# R5SS_ECC_AGG_CORE0_53000000h register map
Vendor: Texas Instruments
Peripheral module from a debugger description file (folder AM263P).
Registers are 32-bit, access not given, reset 0x0 unless marked. A register's access mark holds for its fields unless they carry their own. Offsets are as the file gives them; lines under a group give offsets from that group; [hi:lo] are bit positions; {n}, {i} and the like mark numbered series; 'fields as' and 'values as' point back to an identical list; <NAME> marks a mode.

## ECC_AGG_CORE0
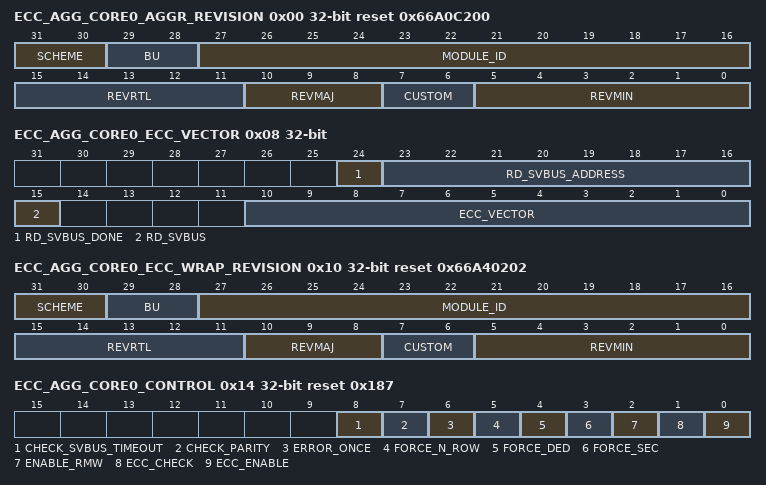
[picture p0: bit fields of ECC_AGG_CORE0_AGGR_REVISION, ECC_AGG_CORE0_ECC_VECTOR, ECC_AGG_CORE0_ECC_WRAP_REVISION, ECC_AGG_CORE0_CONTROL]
0x00 ECC_AGG_CORE0_AGGR_REVISION ro reset 0x66A0C200 — Revision parameters register. The Revision Register contains the major and minor revisions for the ECC aggregator module. It does notsupport byte accesses.
  [31:30] SCHEME
  [29:28] BU
  [27:16] MODULE_ID
  [15:11] REVRTL — RTL version
  [10:8] REVMAJ — Major version
  [7:6] CUSTOM — Custom version
  [5:0] REVMIN — Minor version
0x08 ECC_AGG_CORE0_ECC_VECTOR — ECC Vector Register. ECC RAM ID to select which ECC RAM to control or read status from.
  [24] RD_SVBUS_DONE ro — Status to indicate if read on serial VBUS is complete
  [23:16] RD_SVBUS_ADDRESS rw — Read address
  [15] RD_SVBUS — Write 1 to trigger a read on the serial VBUS (access R/W1TS)
  [10:0] ECC_VECTOR rw — Value written to select the corresponding ECC RAM for control or status
0x0C ECC_AGG_CORE0_MISC_STATUS ro reset 0x1D — Misc Statu register. It contains misc status such as number of ECC RAMs serviced by the ECC aggregator.
  [10:0] NUM_RAMS — Indicates the number of RAMS serviced by the ECC aggregator
0x10 ECC_AGG_CORE0_ECC_WRAP_REVISION ro reset 0x66A40202 — Revision parameters.
  fields as ECC_AGG_CORE0_AGGR_REVISION
0x14 ECC_AGG_CORE0_CONTROL rw reset 0x187 — ECC Control Register.
  [8] CHECK_SVBUS_TIMEOUT — check for svbus timeout errors
  [7] CHECK_PARITY — check for parity errors
  [6] ERROR_ONCE — Force Error only once
  [5] FORCE_N_ROW — Force Error on any RAM read
  [4] FORCE_DED — Force Double Bit Error
  [3] FORCE_SEC — Force Single Bit Error
  [2] ENABLE_RMW
  [1] ECC_CHECK — Enable ECC check
  [0] ECC_ENABLE — Enable ECC
0x18 ECC_AGG_CORE0_ERROR_CTRL1 rw — ECC Error Control1 Register.
  [31:0] ECC_ROW — Row address where single or double-bit error needs to be applied. This is ignored if force_n_row is set
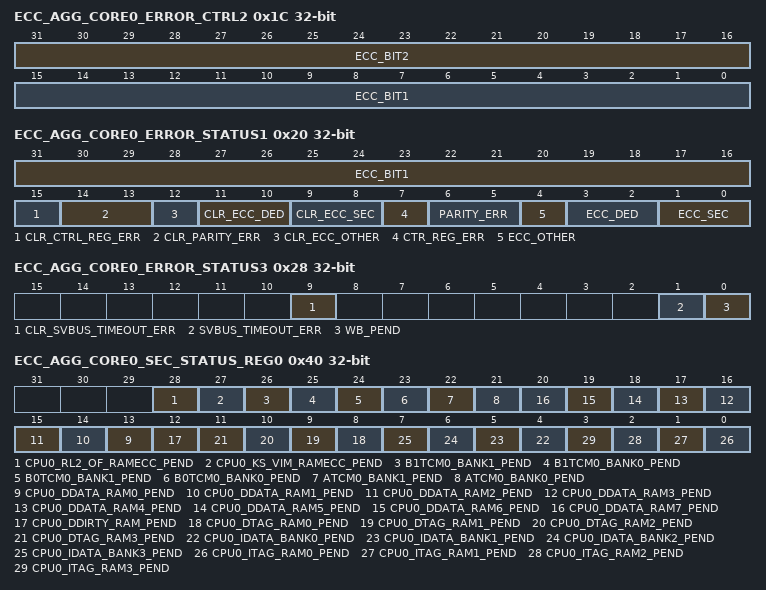
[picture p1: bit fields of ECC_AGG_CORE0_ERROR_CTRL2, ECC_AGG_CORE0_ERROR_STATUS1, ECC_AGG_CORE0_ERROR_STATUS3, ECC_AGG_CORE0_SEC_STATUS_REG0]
0x1C ECC_AGG_CORE0_ERROR_CTRL2 rw — ECC Error Control2 Register.
  [31:16] ECC_BIT2 — Data bit that needs to be flipped if double bit error needs to be forced
  [15:0] ECC_BIT1 — Data bit that needs to be flipped when force_sec is set
0x20 ECC_AGG_CORE0_ERROR_STATUS1 — ECC Error Status1 Register.
  [31:16] ECC_BIT1 ro — Data bit that corresponds to the single-bit error
  [15] CLR_CTRL_REG_ERR — Clear control reg error Error Status, you must also re write the contorl ergister itself to clear this (access R/W1TC)
  [14:13] CLR_PARITY_ERR — Clear parity Error Status (access R/WD)
  [12] CLR_ECC_OTHER — Clear other Error Status (access R/W1TC)
  [11:10] CLR_ECC_DED — Clear Double Bit Error Status (access R/WD)
  [9:8] CLR_ECC_SEC — Clear Single Bit Error Status (access R/WD)
  [7] CTR_REG_ERR — control register error pending, Level interrupt (access R/W1TS)
  [6:5] PARITY_ERR — Level parity error Error Status (access R/W1TS)
  [4] ECC_OTHER — Successive single-bit errors have occurred while a writeback is still pending, Level interrupt (access R/W1TS)
  [3:2] ECC_DED — Level Double Bit Error Status (access R/WI)
  [1:0] ECC_SEC — Level Single Bit Error Status (access R/WI)
0x24 ECC_AGG_CORE0_ERROR_STATUS2 ro — ECC Error Status2 Register.
  [31:0] ECC_ROW — Row address where the single or double-bit error has occurred
0x28 ECC_AGG_CORE0_ERROR_STATUS3 — ECC Error Status3 Register.
  [9] CLR_SVBUS_TIMEOUT_ERR — Clear svbus timeout Error Status (access R/W1TC)
  [1] SVBUS_TIMEOUT_ERR — Level svbus timeout error Error Status (access R/W1TS)
  [0] WB_PEND ro — delayed write back pending Status
0x3C ECC_AGG_CORE0_SEC_EOI_REG — EOI Register.
  [0] EOI_WR — EOI Register (access R/W1TS)
0x40 ECC_AGG_CORE0_SEC_STATUS_REG0 — Interrupt Status Register 0
  [28] CPU0_RL2_OF_RAMECC_PEND — Interrupt Pending Status for cpu0_rl2_of_ramecc_pend (access R/W1TS)
  [27] CPU0_KS_VIM_RAMECC_PEND — Interrupt Pending Status for cpu0_ks_vim_ramecc_pend (access R/W1TS)
  [26] B1TCM0_BANK1_PEND — Interrupt Pending Status for b1tcm0_bank1_pend (access R/W1TS)
  [25] B1TCM0_BANK0_PEND — Interrupt Pending Status for b1tcm0_bank0_pend (access R/W1TS)
  [24] B0TCM0_BANK1_PEND — Interrupt Pending Status for b0tcm0_bank1_pend (access R/W1TS)
  [23] B0TCM0_BANK0_PEND — Interrupt Pending Status for b0tcm0_bank0_pend (access R/W1TS)
  [22] ATCM0_BANK1_PEND — Interrupt Pending Status for atcm0_bank1_pend (access R/W1TS)
  [21] ATCM0_BANK0_PEND — Interrupt Pending Status for atcm0_bank0_pend (access R/W1TS)
  [n+13] CPU0_DDATA_RAM{n}_PEND (n=0..7) — Interrupt Pending Status for cpu0_ddata_ram{n}_pend (access R/W1TS)
  [12] CPU0_DDIRTY_RAM_PEND — Interrupt Pending Status for cpu0_ddirty_ram_pend (access R/W1TS)
  [n+8] CPU0_DTAG_RAM{n}_PEND (n=0..3) — Interrupt Pending Status for cpu0_dtag_ram{n}_pend (access R/W1TS)
  [n+4] CPU0_IDATA_BANK{n}_PEND (n=0..3) — Interrupt Pending Status for cpu0_idata_bank{n}_pend (access R/W1TS)
  [n] CPU0_ITAG_RAM{n}_PEND (n=0..3) — Interrupt Pending Status for cpu0_itag_ram{n}_pend (access R/W1TS)
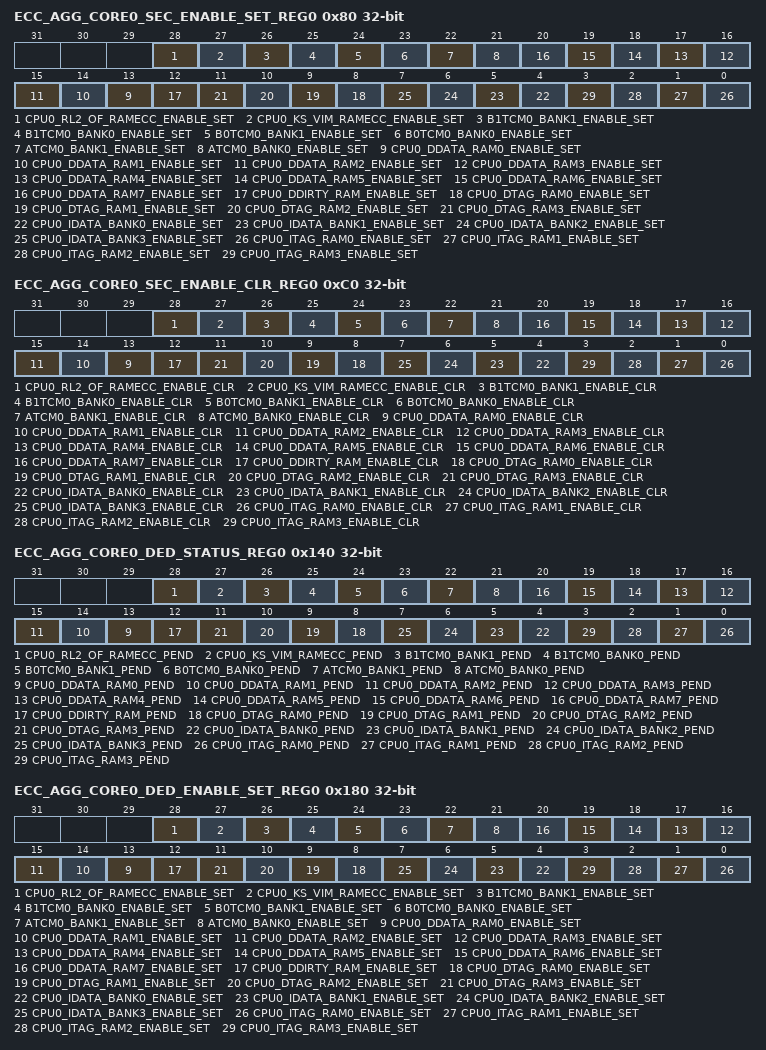
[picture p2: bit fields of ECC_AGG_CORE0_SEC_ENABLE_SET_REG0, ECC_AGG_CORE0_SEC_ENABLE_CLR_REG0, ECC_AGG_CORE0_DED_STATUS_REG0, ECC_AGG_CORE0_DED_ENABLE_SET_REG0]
0x80 ECC_AGG_CORE0_SEC_ENABLE_SET_REG0 — Interrupt Enable Set Register 0
  [28] CPU0_RL2_OF_RAMECC_ENABLE_SET — Interrupt Enable Set Register for cpu0_rl2_of_ramecc_pend (access R/W1TS)
  [27] CPU0_KS_VIM_RAMECC_ENABLE_SET — Interrupt Enable Set Register for cpu0_ks_vim_ramecc_pend (access R/W1TS)
  [26] B1TCM0_BANK1_ENABLE_SET — Interrupt Enable Set Register for b1tcm0_bank1_pend (access R/W1TS)
  [25] B1TCM0_BANK0_ENABLE_SET — Interrupt Enable Set Register for b1tcm0_bank0_pend (access R/W1TS)
  [24] B0TCM0_BANK1_ENABLE_SET — Interrupt Enable Set Register for b0tcm0_bank1_pend (access R/W1TS)
  [23] B0TCM0_BANK0_ENABLE_SET — Interrupt Enable Set Register for b0tcm0_bank0_pend (access R/W1TS)
  [22] ATCM0_BANK1_ENABLE_SET — Interrupt Enable Set Register for atcm0_bank1_pend (access R/W1TS)
  [21] ATCM0_BANK0_ENABLE_SET — Interrupt Enable Set Register for atcm0_bank0_pend (access R/W1TS)
  [n+13] CPU0_DDATA_RAM{n}_ENABLE_SET (n=0..7) — Interrupt Enable Set Register for cpu0_ddata_ram{n}_pend (access R/W1TS)
  [12] CPU0_DDIRTY_RAM_ENABLE_SET — Interrupt Enable Set Register for cpu0_ddirty_ram_pend (access R/W1TS)
  [n+8] CPU0_DTAG_RAM{n}_ENABLE_SET (n=0..3) — Interrupt Enable Set Register for cpu0_dtag_ram{n}_pend (access R/W1TS)
  [n+4] CPU0_IDATA_BANK{n}_ENABLE_SET (n=0..3) — Interrupt Enable Set Register for cpu0_idata_bank{n}_pend (access R/W1TS)
  [n] CPU0_ITAG_RAM{n}_ENABLE_SET (n=0..3) — Interrupt Enable Set Register for cpu0_itag_ram{n}_pend (access R/W1TS)
0xC0 ECC_AGG_CORE0_SEC_ENABLE_CLR_REG0 — Interrupt Enable Clear Register 0
  [28] CPU0_RL2_OF_RAMECC_ENABLE_CLR — Interrupt Enable Clear Register for cpu0_rl2_of_ramecc_pend (access R/W1TC)
  [27] CPU0_KS_VIM_RAMECC_ENABLE_CLR — Interrupt Enable Clear Register for cpu0_ks_vim_ramecc_pend (access R/W1TC)
  [26] B1TCM0_BANK1_ENABLE_CLR — Interrupt Enable Clear Register for b1tcm0_bank1_pend (access R/W1TC)
  [25] B1TCM0_BANK0_ENABLE_CLR — Interrupt Enable Clear Register for b1tcm0_bank0_pend (access R/W1TC)
  [24] B0TCM0_BANK1_ENABLE_CLR — Interrupt Enable Clear Register for b0tcm0_bank1_pend (access R/W1TC)
  [23] B0TCM0_BANK0_ENABLE_CLR — Interrupt Enable Clear Register for b0tcm0_bank0_pend (access R/W1TC)
  [22] ATCM0_BANK1_ENABLE_CLR — Interrupt Enable Clear Register for atcm0_bank1_pend (access R/W1TC)
  [21] ATCM0_BANK0_ENABLE_CLR — Interrupt Enable Clear Register for atcm0_bank0_pend (access R/W1TC)
  [n+13] CPU0_DDATA_RAM{n}_ENABLE_CLR (n=0..7) — Interrupt Enable Clear Register for cpu0_ddata_ram{n}_pend (access R/W1TC)
  [12] CPU0_DDIRTY_RAM_ENABLE_CLR — Interrupt Enable Clear Register for cpu0_ddirty_ram_pend (access R/W1TC)
  [n+8] CPU0_DTAG_RAM{n}_ENABLE_CLR (n=0..3) — Interrupt Enable Clear Register for cpu0_dtag_ram{n}_pend (access R/W1TC)
  [n+4] CPU0_IDATA_BANK{n}_ENABLE_CLR (n=0..3) — Interrupt Enable Clear Register for cpu0_idata_bank{n}_pend (access R/W1TC)
  [n] CPU0_ITAG_RAM{n}_ENABLE_CLR (n=0..3) — Interrupt Enable Clear Register for cpu0_itag_ram{n}_pend (access R/W1TC)
0x13C ECC_AGG_CORE0_DED_EOI_REG — EOI Register.
  [0] EOI_WR — EOI Register (access R/W1TS)
0x140 ECC_AGG_CORE0_DED_STATUS_REG0 — Interrupt Status Register 0
  fields as ECC_AGG_CORE0_SEC_STATUS_REG0
0x180 ECC_AGG_CORE0_DED_ENABLE_SET_REG0 — Interrupt Enable Set Register 0
  fields as ECC_AGG_CORE0_SEC_ENABLE_SET_REG0
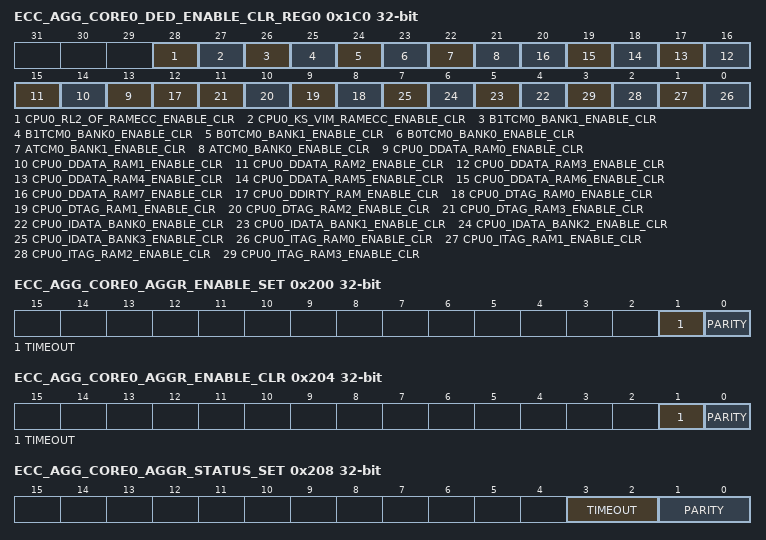
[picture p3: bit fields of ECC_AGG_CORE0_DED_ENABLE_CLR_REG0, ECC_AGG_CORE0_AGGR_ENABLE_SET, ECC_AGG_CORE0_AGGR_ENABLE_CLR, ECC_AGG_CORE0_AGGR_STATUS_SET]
0x1C0 ECC_AGG_CORE0_DED_ENABLE_CLR_REG0 — Interrupt Enable Clear Register 0
  fields as ECC_AGG_CORE0_SEC_ENABLE_CLR_REG0
0x200 ECC_AGG_CORE0_AGGR_ENABLE_SET — AGGR interrupt enable set Register.
  [1] TIMEOUT — Interrupt enable set for svbus timeout errors (access R/W1TS)
  [0] PARITY — Interrupt enable set for parity errors (access R/W1TS)
0x204 ECC_AGG_CORE0_AGGR_ENABLE_CLR — AGGR interrupt enable clear Register.
  [1] TIMEOUT — Interrupt enable clear for svbus timeout errors (access R/W1TC)
  [0] PARITY — Interrupt enable clear for parity errors (access R/W1TC)
0x208 ECC_AGG_CORE0_AGGR_STATUS_SET — AGGR interrupt status set Register.
  [3:2] TIMEOUT — Interrupt status set for svbus timeout errors. 2-bit saturating counter of the number of timeout errors that have occurred since last cleared. 0x0: No timeout errors have occurred 0x1: 1 timeout erro has occurred 0x2: 2 timeout error has occurred 0x3: 3 or more timeout errors have occurred A write of a non-zero value to this register increments that many from the timeout fields. If the value written is less than the current value of the counter, then the pending level interrupt stays asserted. . If this register goes from 0 to non zero a level interrupt will be asserted as well as a pulse interrupt. If the value was non zero to non zero then the level interrupt would remain asserted, but no new pulse interrupt would be asserted. You must write the eoi register to get a new pulse interrupt. (access R/WI)
  [1:0] PARITY — Interrupt status set for parity errors. 2-bit saturating counter of the number of parity errors that have occurred since last cleared. 0x0: No parity errors have occurred 0x1: 1 parity error has occurred 0x2: 2 parity error has occurred 0x3 3 or more parity error have occurred A write of a non-zero value to this register incrments that many from the parity fields. If the value written is less than the current value of the counter, then the pending level interrupt stays asserted. If this register goes from 0 to non zero a level interrupt will be asserted as well as a pulse interrupt. If the value was non zero to non zero then the level interrupt would remain asserted, but no new pulse interrupt would be asserted. You must write the eoi register to get a new pulse interrupt. (access R/WI)
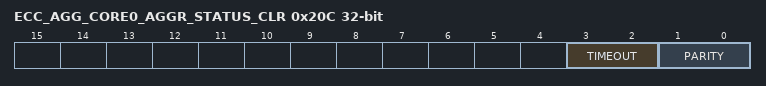
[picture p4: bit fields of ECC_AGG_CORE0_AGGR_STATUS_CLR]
0x20C ECC_AGG_CORE0_AGGR_STATUS_CLR — AGGR interrupt status clear Register.
  [3:2] TIMEOUT — Interrupt status clear for svbus timeout errors. 0x0: No timeout errors have occurred 0x1: 1 timeout error has occurred 0x2: 2 timeout error has occurred 0x3: 3 or more timeout error have occurred A write of a non-zero value to this register decrements that many from the timeout fields. If the resulting written value is non zero, then the pending level interrupt stays asserted. A new pulse interrupt will not be asserted, you must write the eoi register for that to occur. If you write a value more than the counter value the result will be zero. (access R/WD)
  [1:0] PARITY — Interrupt status clear for parity errors. 0x0: No parity errors have occurred 0x1: 1 parity error has occurred 0x2: 2 parity error has occurred 0x3: 3 or more parity error have occurred A write of a non-zero value to this register decrements that many from the parity fields. If the resulting written value is non zero, then the pending level interrupt stays asserted. A new pulse interrupt will not be asserted, you must write the eoi register for that to occur. If you write a value more than the counter value the result will be zero. (access R/WD)
